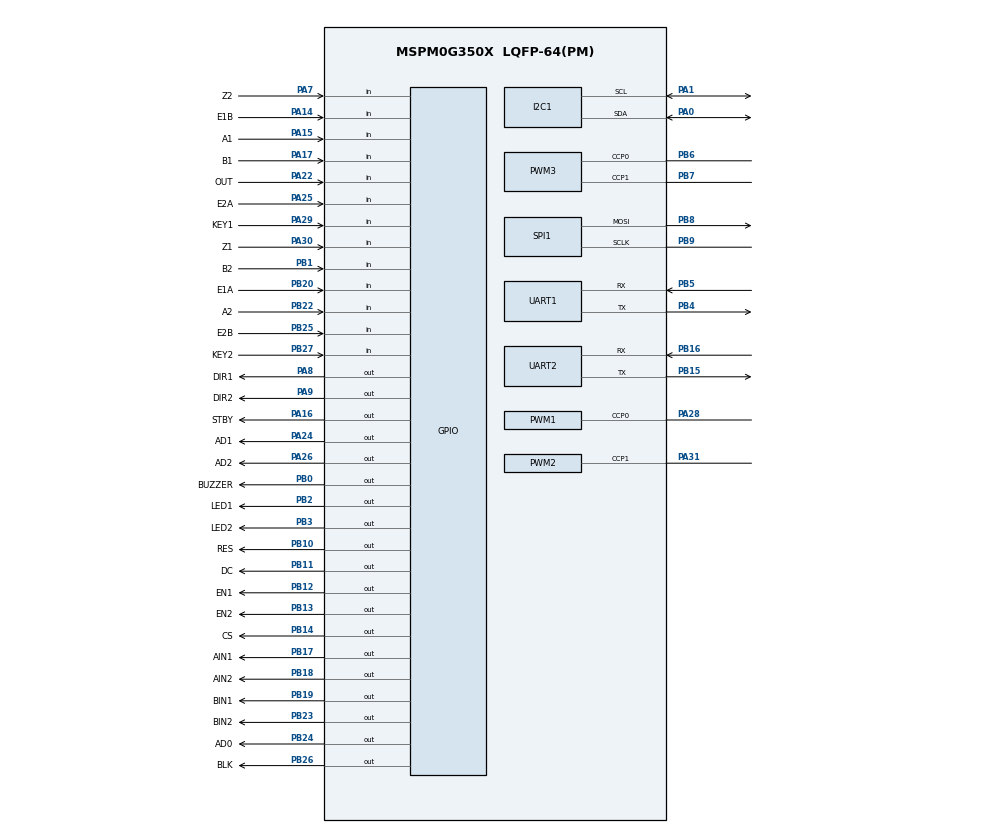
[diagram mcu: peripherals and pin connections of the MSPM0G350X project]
/**
 * @cliArgs --device "MSPM0G350X" --part "Default" --package "LQFP-64(PM)" --product "mspm0_sdk@2.11.00.07"
 * @versions {"tool":"1.26.2+4477"}
 */

/**
 * Import the modules used in this configuration.
 */
const GPIO    = scripting.addModule("/ti/driverlib/GPIO", {}, false);
const GPIO1   = GPIO.addInstance();
const GPIO2   = GPIO.addInstance();
const GPIO3   = GPIO.addInstance();
const GPIO4   = GPIO.addInstance();
const GPIO5   = GPIO.addInstance();
const GPIO6   = GPIO.addInstance();
const GPIO7   = GPIO.addInstance();
const GPIO8   = GPIO.addInstance();
const GPIO9   = GPIO.addInstance();
const I2C     = scripting.addModule("/ti/driverlib/I2C", {}, false);
const I2C1    = I2C.addInstance();
const PWM     = scripting.addModule("/ti/driverlib/PWM", {}, false);
const PWM1    = PWM.addInstance();
const PWM2    = PWM.addInstance();
const PWM3    = PWM.addInstance();
const SPI     = scripting.addModule("/ti/driverlib/SPI", {}, false);
const SPI1    = SPI.addInstance();
const SYSCTL  = scripting.addModule("/ti/driverlib/SYSCTL");
const SYSTICK = scripting.addModule("/ti/driverlib/SYSTICK");
const TIMER   = scripting.addModule("/ti/driverlib/TIMER", {}, false);
const TIMER1  = TIMER.addInstance();
const UART    = scripting.addModule("/ti/driverlib/UART", {}, false);
const UART1   = UART.addInstance();
const UART2   = UART.addInstance();

/**
 * Write custom configuration values to the imported modules.
 */
const multiplier2         = system.clockTree["PLL_QDIV"];
multiplier2.multiplyValue = 4;

const mux4       = system.clockTree["EXHFMUX"];
mux4.inputSelect = "EXHFMUX_XTAL";

GPIO1.$name                         = "sm_motor";
GPIO1.associatedPins.create(4);
GPIO1.associatedPins[0].$name       = "DIR1";
GPIO1.associatedPins[0].pin.$assign = "PA8";
GPIO1.associatedPins[1].$name       = "EN1";
GPIO1.associatedPins[1].pin.$assign = "PB12";
GPIO1.associatedPins[2].$name       = "DIR2";
GPIO1.associatedPins[2].pin.$assign = "PA9";
GPIO1.associatedPins[3].$name       = "EN2";
GPIO1.associatedPins[3].pin.$assign = "PB13";

const Board = scripting.addModule("/ti/driverlib/Board", {}, false);

GPIO2.$name                         = "sm_motor_encoder";
GPIO2.associatedPins.create(6);
GPIO2.associatedPins[0].direction   = "INPUT";
GPIO2.associatedPins[0].$name       = "A1";
GPIO2.associatedPins[0].polarity    = "RISE_FALL";
GPIO2.associatedPins[0].pin.$assign = "PA15";
GPIO2.associatedPins[1].$name       = "B1";
GPIO2.associatedPins[1].direction   = "INPUT";
GPIO2.associatedPins[1].polarity    = "RISE_FALL";
GPIO2.associatedPins[1].pin.$assign = "PA17";
GPIO2.associatedPins[2].$name       = "Z1";
GPIO2.associatedPins[2].direction   = "INPUT";
GPIO2.associatedPins[2].polarity    = "RISE";
GPIO2.associatedPins[2].pin.$assign = "PA30";
GPIO2.associatedPins[3].$name       = "A2";
GPIO2.associatedPins[3].direction   = "INPUT";
GPIO2.associatedPins[3].polarity    = "RISE_FALL";
GPIO2.associatedPins[3].pin.$assign = "PB22";
GPIO2.associatedPins[4].$name       = "B2";
GPIO2.associatedPins[4].direction   = "INPUT";
GPIO2.associatedPins[4].polarity    = "RISE_FALL";
GPIO2.associatedPins[4].pin.$assign = "PB1";
GPIO2.associatedPins[5].$name       = "Z2";
GPIO2.associatedPins[5].direction   = "INPUT";
GPIO2.associatedPins[5].polarity    = "RISE";
GPIO2.associatedPins[5].pin.$assign = "PA7";

GPIO3.$name                         = "led";
GPIO3.associatedPins.create(2);
GPIO3.associatedPins[0].$name       = "LED1";
GPIO3.associatedPins[0].pin.$assign = "PB2";
GPIO3.associatedPins[1].$name       = "LED2";
GPIO3.associatedPins[1].pin.$assign = "PB3";

GPIO4.$name                              = "key";
GPIO4.associatedPins.create(2);
GPIO4.associatedPins[0].$name            = "KEY1";
GPIO4.associatedPins[0].internalResistor = "PULL_UP";
GPIO4.associatedPins[0].direction        = "INPUT";
GPIO4.associatedPins[0].pin.$assign      = "PA29";
GPIO4.associatedPins[1].$name            = "KEY2";
GPIO4.associatedPins[1].direction        = "INPUT";
GPIO4.associatedPins[1].internalResistor = "PULL_UP";
GPIO4.associatedPins[1].pin.$assign      = "PB27";

GPIO5.$name                         = "buzzer";
GPIO5.associatedPins[0].$name       = "BUZZER";
GPIO5.associatedPins[0].pin.$assign = "PB0";

GPIO6.$name                         = "motor";
GPIO6.associatedPins.create(5);
GPIO6.associatedPins[0].$name       = "AIN1";
GPIO6.associatedPins[0].pin.$assign = "PB17";
GPIO6.associatedPins[1].$name       = "AIN2";
GPIO6.associatedPins[1].pin.$assign = "PB18";
GPIO6.associatedPins[2].$name       = "BIN1";
GPIO6.associatedPins[2].pin.$assign = "PB19";
GPIO6.associatedPins[3].$name       = "BIN2";
GPIO6.associatedPins[3].pin.$assign = "PB23";
GPIO6.associatedPins[4].$name       = "STBY";
GPIO6.associatedPins[4].pin.$assign = "PA16";

GPIO7.$name                              = "encoder";
GPIO7.associatedPins.create(4);
GPIO7.associatedPins[0].$name            = "E1A";
GPIO7.associatedPins[0].direction        = "INPUT";
GPIO7.associatedPins[0].interruptEn      = true;
GPIO7.associatedPins[0].polarity         = "RISE";
GPIO7.associatedPins[0].internalResistor = "PULL_DOWN";
GPIO7.associatedPins[0].pin.$assign      = "PB20";
GPIO7.associatedPins[1].$name            = "E1B";
GPIO7.associatedPins[1].direction        = "INPUT";
GPIO7.associatedPins[1].internalResistor = "PULL_DOWN";
GPIO7.associatedPins[1].polarity         = "RISE";
GPIO7.associatedPins[1].pin.$assign      = "PA14";
GPIO7.associatedPins[2].$name            = "E2A";
GPIO7.associatedPins[2].direction        = "INPUT";
GPIO7.associatedPins[2].interruptEn      = true;
GPIO7.associatedPins[2].internalResistor = "PULL_DOWN";
GPIO7.associatedPins[2].polarity         = "RISE";
GPIO7.associatedPins[2].pin.$assign      = "PA25";
GPIO7.associatedPins[3].$name            = "E2B";
GPIO7.associatedPins[3].direction        = "INPUT";
GPIO7.associatedPins[3].internalResistor = "PULL_DOWN";
GPIO7.associatedPins[3].polarity         = "RISE";
GPIO7.associatedPins[3].pin.$assign      = "PB25";

GPIO8.$name                         = "GrayS";
GPIO8.associatedPins.create(4);
GPIO8.associatedPins[0].$name       = "OUT";
GPIO8.associatedPins[0].direction   = "INPUT";
GPIO8.associatedPins[0].pin.$assign = "PA22";
GPIO8.associatedPins[1].$name       = "AD0";
GPIO8.associatedPins[1].pin.$assign = "PB24";
GPIO8.associatedPins[2].$name       = "AD1";
GPIO8.associatedPins[2].pin.$assign = "PA24";
GPIO8.associatedPins[3].$name       = "AD2";
GPIO8.associatedPins[3].pin.$assign = "PA26";

GPIO9.$name                          = "oled";
GPIO9.associatedPins.create(4);
GPIO9.associatedPins[0].$name        = "RES";
GPIO9.associatedPins[0].initialValue = "SET";
GPIO9.associatedPins[0].pin.$assign  = "PB10";
GPIO9.associatedPins[1].$name        = "DC";
GPIO9.associatedPins[1].pin.$assign  = "PB11";
GPIO9.associatedPins[2].$name        = "CS";
GPIO9.associatedPins[2].initialValue = "SET";
GPIO9.associatedPins[2].pin.$assign  = "PB14";
GPIO9.associatedPins[3].$name        = "BLK";
GPIO9.associatedPins[3].initialValue = "SET";
GPIO9.associatedPins[3].pin.$assign  = "PB26";

I2C1.$name                             = "MPU6050";
I2C1.basicEnableController             = true;
I2C1.peripheral.$assign                = "I2C0";
I2C1.peripheral.sdaPin.$assign         = "PA0";
I2C1.peripheral.sclPin.$assign         = "PA1";
I2C1.sdaPinConfig.$name                = "ti_driverlib_gpio_GPIOPinGeneric0";
I2C1.sdaPinConfig.hideOutputInversion  = scripting.forceWrite(false);
I2C1.sdaPinConfig.onlyInternalResistor = scripting.forceWrite(false);
I2C1.sdaPinConfig.passedPeripheralType = scripting.forceWrite("Digital");
I2C1.sclPinConfig.$name                = "ti_driverlib_gpio_GPIOPinGeneric1";
I2C1.sclPinConfig.hideOutputInversion  = scripting.forceWrite(false);
I2C1.sclPinConfig.onlyInternalResistor = scripting.forceWrite(false);
I2C1.sclPinConfig.passedPeripheralType = scripting.forceWrite("Digital");

PWM1.clockDivider                       = 8;
PWM1.timerCount                         = 20000;
PWM1.ccIndex                            = [0];
PWM1.$name                              = "sm_motor_ST1";
PWM1.clockPrescale                      = 10;
PWM1.PWM_CHANNEL_0.$name                = "ti_driverlib_pwm_PWMTimerCC0";
PWM1.ccp0PinConfig.$name                = "ti_driverlib_gpio_GPIOPinGeneric2";
PWM1.ccp0PinConfig.direction            = scripting.forceWrite("OUTPUT");
PWM1.ccp0PinConfig.hideOutputInversion  = scripting.forceWrite(false);
PWM1.ccp0PinConfig.onlyInternalResistor = scripting.forceWrite(false);
PWM1.ccp0PinConfig.passedPeripheralType = scripting.forceWrite("Digital");
PWM1.peripheral.$assign                 = "TIMA1";
PWM1.peripheral.ccp0Pin.$assign         = "PA28";

PWM2.$name                              = "sm_motor_ST2";
PWM2.clockDivider                       = 8;
PWM2.timerCount                         = 20000;
PWM2.ccIndex                            = [1];
PWM2.ccp1PinConfig.direction            = scripting.forceWrite("OUTPUT");
PWM2.ccp1PinConfig.hideOutputInversion  = scripting.forceWrite(false);
PWM2.ccp1PinConfig.onlyInternalResistor = scripting.forceWrite(false);
PWM2.ccp1PinConfig.passedPeripheralType = scripting.forceWrite("Digital");
PWM2.ccp1PinConfig.$name                = "ti_driverlib_gpio_GPIOPinGeneric6";
PWM2.peripheral.$assign                 = "TIMG12";
PWM2.peripheral.ccp1Pin.$assign         = "PA31";
PWM2.PWM_CHANNEL_1.$name                = "ti_driverlib_pwm_PWMTimerCC1";

PWM3.$name                              = "motor_pwm";
PWM3.clockDivider                       = 2;
PWM3.peripheral.$assign                 = "TIMG8";
PWM3.peripheral.ccp0Pin.$assign         = "PB6";
PWM3.peripheral.ccp1Pin.$assign         = "PB7";
PWM3.PWM_CHANNEL_0.$name                = "ti_driverlib_pwm_PWMTimerCC2";
PWM3.PWM_CHANNEL_0.invert               = true;
PWM3.PWM_CHANNEL_1.$name                = "ti_driverlib_pwm_PWMTimerCC3";
PWM3.PWM_CHANNEL_1.invert               = true;
PWM3.ccp0PinConfig.direction            = scripting.forceWrite("OUTPUT");
PWM3.ccp0PinConfig.hideOutputInversion  = scripting.forceWrite(false);
PWM3.ccp0PinConfig.onlyInternalResistor = scripting.forceWrite(false);
PWM3.ccp0PinConfig.passedPeripheralType = scripting.forceWrite("Digital");
PWM3.ccp0PinConfig.$name                = "ti_driverlib_gpio_GPIOPinGeneric8";
PWM3.ccp1PinConfig.direction            = scripting.forceWrite("OUTPUT");
PWM3.ccp1PinConfig.hideOutputInversion  = scripting.forceWrite(false);
PWM3.ccp1PinConfig.onlyInternalResistor = scripting.forceWrite(false);
PWM3.ccp1PinConfig.passedPeripheralType = scripting.forceWrite("Digital");
PWM3.ccp1PinConfig.$name                = "ti_driverlib_gpio_GPIOPinGeneric9";

SPI1.$name                              = "OLED";
SPI1.peripheral.$assign                 = "SPI1";
SPI1.peripheral.sclkPin.$assign         = "PB9";
SPI1.peripheral.mosiPin.$assign         = "PB8";
SPI1.sclkPinConfig.direction            = scripting.forceWrite("OUTPUT");
SPI1.sclkPinConfig.onlyInternalResistor = scripting.forceWrite(false);
SPI1.sclkPinConfig.passedPeripheralType = scripting.forceWrite("Digital");
SPI1.sclkPinConfig.$name                = "ti_driverlib_gpio_GPIOPinGeneric10";
SPI1.mosiPinConfig.direction            = scripting.forceWrite("OUTPUT");
SPI1.mosiPinConfig.hideOutputInversion  = scripting.forceWrite(false);
SPI1.mosiPinConfig.onlyInternalResistor = scripting.forceWrite(false);
SPI1.mosiPinConfig.passedPeripheralType = scripting.forceWrite("Digital");
SPI1.mosiPinConfig.$name                = "ti_driverlib_gpio_GPIOPinGeneric11";
SPI1.misoPinConfig.onlyInternalResistor = scripting.forceWrite(false);
SPI1.misoPinConfig.passedPeripheralType = scripting.forceWrite("Digital");
SPI1.misoPinConfig.$name                = "ti_driverlib_gpio_GPIOPinGeneric12";
SPI1.cs0PinConfig.direction             = scripting.forceWrite("OUTPUT");
SPI1.cs0PinConfig.hideOutputInversion   = scripting.forceWrite(false);
SPI1.cs0PinConfig.onlyInternalResistor  = scripting.forceWrite(false);
SPI1.cs0PinConfig.passedPeripheralType  = scripting.forceWrite("Digital");
SPI1.cs0PinConfig.$name                 = "ti_driverlib_gpio_GPIOPinGeneric13";

SYSCTL.forceDefaultClkConfig = true;
SYSCTL.clockTreeEn           = true;

TIMER1.timerPeriod        = "50 ms";
TIMER1.timerClkDiv        = 2;
TIMER1.timerClkPrescale   = 50;
TIMER1.$name              = "key_encoder";
TIMER1.timerMode          = "PERIODIC_UP";
TIMER1.peripheral.$assign = "TIMG7";

UART1.$name                            = "smotor_vision";
UART1.targetBaudRate                   = 115200;
UART1.peripheral.$assign               = "UART1";
UART1.peripheral.rxPin.$assign         = "PB5";
UART1.peripheral.txPin.$assign         = "PB4";
UART1.txPinConfig.direction            = scripting.forceWrite("OUTPUT");
UART1.txPinConfig.hideOutputInversion  = scripting.forceWrite(false);
UART1.txPinConfig.onlyInternalResistor = scripting.forceWrite(false);
UART1.txPinConfig.passedPeripheralType = scripting.forceWrite("Digital");
UART1.txPinConfig.$name                = "ti_driverlib_gpio_GPIOPinGeneric4";
UART1.rxPinConfig.hideOutputInversion  = scripting.forceWrite(false);
UART1.rxPinConfig.onlyInternalResistor = scripting.forceWrite(false);
UART1.rxPinConfig.passedPeripheralType = scripting.forceWrite("Digital");
UART1.rxPinConfig.$name                = "ti_driverlib_gpio_GPIOPinGeneric5";

UART2.$name                            = "PC_uart";
UART2.targetBaudRate                   = 115200;
UART2.peripheral.$assign               = "UART2";
UART2.peripheral.rxPin.$assign         = "PB16";
UART2.peripheral.txPin.$assign         = "PB15";
UART2.txPinConfig.direction            = scripting.forceWrite("OUTPUT");
UART2.txPinConfig.hideOutputInversion  = scripting.forceWrite(false);
UART2.txPinConfig.onlyInternalResistor = scripting.forceWrite(false);
UART2.txPinConfig.passedPeripheralType = scripting.forceWrite("Digital");
UART2.txPinConfig.$name                = "ti_driverlib_gpio_GPIOPinGeneric3";
UART2.rxPinConfig.hideOutputInversion  = scripting.forceWrite(false);
UART2.rxPinConfig.onlyInternalResistor = scripting.forceWrite(false);
UART2.rxPinConfig.passedPeripheralType = scripting.forceWrite("Digital");
UART2.rxPinConfig.$name                = "ti_driverlib_gpio_GPIOPinGeneric7";

/**
 * Pinmux solution for unlocked pins/peripherals. This ensures that minor changes to the automatic solver in a future
 * version of the tool will not impact the pinmux you originally saw.  These lines can be completely deleted in order to
 * re-solve from scratch.
 */
Board.peripheral.$suggestSolution          = "DEBUGSS";
Board.peripheral.swclkPin.$suggestSolution = "PA20";
Board.peripheral.swdioPin.$suggestSolution = "PA19";
SPI1.peripheral.misoPin.$suggestSolution   = "PB21";
SPI1.peripheral.cs0Pin.$suggestSolution    = "PA2";
